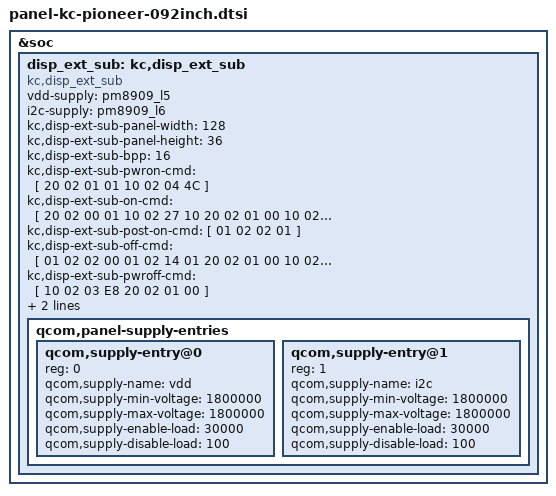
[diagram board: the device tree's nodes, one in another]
/*
 * This software is contributed or developed by KYOCERA Corporation.
 * (C) 2016 KYOCERA Corporation
 *
 * This program is free software; you can redistribute it and/or modify
 * it under the terms of the GNU General Public License version 2 and
 * only version 2 as published by the Free Software Foundation.
 *
 * This program is distributed in the hope that it will be useful,
 * but WITHOUT ANY WARRANTY; without even the implied warranty of
 * MERCHANTABILITY or FITNESS FOR A PARTICULAR PURPOSE.  See the
 * GNU General Public License for more details.
 */

&soc {
	disp_ext_sub: kc,disp_ext_sub {
		compatible = "kc,disp_ext_sub";
		vdd-supply = <&pm8909_l5>;
		i2c-supply = <&pm8909_l6>;
		kc,disp-ext-sub-panel-width = <128>;
		kc,disp-ext-sub-panel-height = <36>;
		kc,disp-ext-sub-bpp = <16>;
		kc,disp-ext-sub-pwron-cmd = [
							20 02 01 01
							10 02 04 4C
				];
		kc,disp-ext-sub-on-cmd = [
							20 02 00 01
							10 02 27 10
							20 02 01 00
							10 02 00 32
							20 02 01 01
							10 02 04 4C
							01 02 02 00
							01 02 14 01
							01 02 1A 05
							01 02 1D 00
							01 02 09 00
							01 03 30 00 7F
							01 03 32 00 23
							01 02 38 00
							01 02 39 00
							01 02 34 00
							01 02 35 0F
							01 02 36 00
							01 02 37 23
							01 02 10 04
							01 02 16 00
							01 02 12 56
							01 02 18 0E
							01 02 44 02
							01 02 48 03
							01 02 17 00
							01 02 13 00
							01 02 1C 00
							01 02 3F 11
							01 02 3D 01
							01 02 C0 00
							01 02 C2 00
							01 02 C3 00
							01 02 C4 00
							01 02 CC 00
							01 02 CD 00
							01 02 CE 02
							01 02 14 00
				];
		kc,disp-ext-sub-post-on-cmd = [
							01 02 02 01
				];
		kc,disp-ext-sub-off-cmd = [
							01 02 02 00
							01 02 14 01

							20 02 01 00
							10 02 00 32
							20 02 01 01
							10 02 04 4C

							20 02 00 00
							10 02 C3 50
				];
		kc,disp-ext-sub-pwroff-cmd = [
							10 02 03 E8
							20 02 01 00
				];
		kc,disp-ext-sub-ram-wr-cmd = [
							01 02 38 00
							01 02 39 00
							01 02 34 00
							01 02 35 0F
							01 02 36 00
							01 02 37 23
				];

		qcom,panel-supply-entries {
			#address-cells = <1>;
			#size-cells = <0>;

			qcom,supply-entry@0 {
				reg = <0>;
				qcom,supply-name = "vdd";
				qcom,supply-min-voltage = <1800000>;
				qcom,supply-max-voltage = <1800000>;
				qcom,supply-enable-load = <30000>;
				qcom,supply-disable-load = <100>;
			};
			qcom,supply-entry@1 {
				reg = <1>;
				qcom,supply-name = "i2c";
				qcom,supply-min-voltage = <1800000>;
				qcom,supply-max-voltage = <1800000>;
				qcom,supply-enable-load = <30000>;
				qcom,supply-disable-load = <100>;
			};
		};
	};
};
